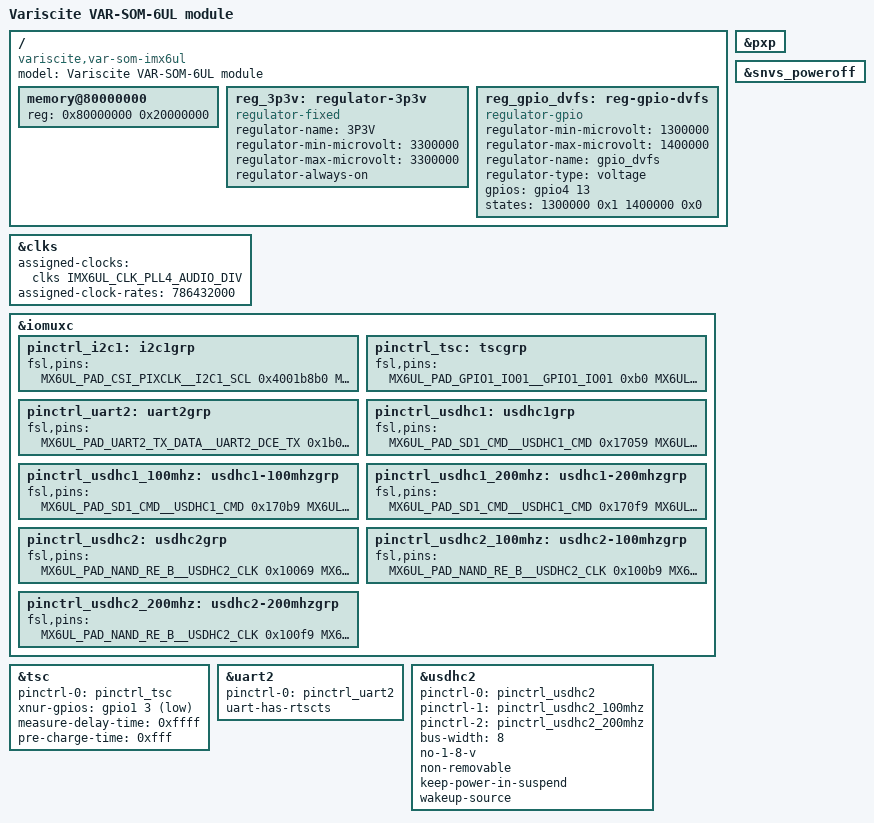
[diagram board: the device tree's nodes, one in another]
// SPDX-License-Identifier: GPL-2.0+
/*
 * Support for the common parts shared by all the different CPU options on
 * Variscite VAR-SOM-6UL Module
 *
 * Copyright 2019 Variscite Ltd.
 * Copyright 2025 Bootlin
 */

#include <dt-bindings/clock/imx6ul-clock.h>
#include <dt-bindings/gpio/gpio.h>

/ {
	model = "Variscite VAR-SOM-6UL module";
	compatible = "variscite,var-som-imx6ul", "fsl,imx6ul";

	memory@80000000 {
		device_type = "memory";
		reg = <0x80000000 0x20000000>;
	};

	reg_3p3v: regulator-3p3v {
		compatible = "regulator-fixed";
		regulator-name = "3P3V";
		regulator-min-microvolt = <3300000>;
		regulator-max-microvolt = <3300000>;
		regulator-always-on;
	};

	reg_gpio_dvfs: reg-gpio-dvfs {
		compatible = "regulator-gpio";
		regulator-min-microvolt = <1300000>;
		regulator-max-microvolt = <1400000>;
		regulator-name = "gpio_dvfs";
		regulator-type = "voltage";
		gpios = <&gpio4 13 GPIO_ACTIVE_HIGH>;
		states = <1300000 0x1
			  1400000 0x0>;
	};
};

&clks {
	assigned-clocks = <&clks IMX6UL_CLK_PLL4_AUDIO_DIV>;
	assigned-clock-rates = <786432000>;
};

&iomuxc {
	pinctrl_i2c1: i2c1grp {
		fsl,pins = <
			MX6UL_PAD_CSI_PIXCLK__I2C1_SCL		0x4001b8b0
			MX6UL_PAD_CSI_MCLK__I2C1_SDA		0x4001b8b0
		>;
	};

	pinctrl_tsc: tscgrp {
		fsl,pins = <
			MX6UL_PAD_GPIO1_IO01__GPIO1_IO01	0xb0
			MX6UL_PAD_GPIO1_IO02__GPIO1_IO02	0xb0
			MX6UL_PAD_GPIO1_IO03__GPIO1_IO03	0xb0
			MX6UL_PAD_GPIO1_IO04__GPIO1_IO04	0xb0
		>;
	};

	pinctrl_uart2: uart2grp {
		fsl,pins = <
			MX6UL_PAD_UART2_TX_DATA__UART2_DCE_TX	0x1b0b1
			MX6UL_PAD_UART2_RX_DATA__UART2_DCE_RX	0x1b0b1
			MX6UL_PAD_UART2_CTS_B__UART2_DCE_CTS	0x1b0b1
			MX6UL_PAD_UART2_RTS_B__UART2_DCE_RTS	0x1b0b1
		>;
	};

	pinctrl_usdhc1: usdhc1grp {
		fsl,pins = <
			MX6UL_PAD_SD1_CMD__USDHC1_CMD		0x17059
			MX6UL_PAD_SD1_CLK__USDHC1_CLK		0x17059
			MX6UL_PAD_SD1_DATA0__USDHC1_DATA0	0x17059
			MX6UL_PAD_SD1_DATA1__USDHC1_DATA1	0x17059
			MX6UL_PAD_SD1_DATA2__USDHC1_DATA2	0x17059
			MX6UL_PAD_SD1_DATA3__USDHC1_DATA3	0x17059
		>;
	};

	pinctrl_usdhc1_100mhz: usdhc1-100mhzgrp {
		fsl,pins = <
			MX6UL_PAD_SD1_CMD__USDHC1_CMD		0x170b9
			MX6UL_PAD_SD1_CLK__USDHC1_CLK		0x100b9
			MX6UL_PAD_SD1_DATA0__USDHC1_DATA0	0x170b9
			MX6UL_PAD_SD1_DATA1__USDHC1_DATA1	0x170b9
			MX6UL_PAD_SD1_DATA2__USDHC1_DATA2	0x170b9
			MX6UL_PAD_SD1_DATA3__USDHC1_DATA3	0x170b9
		>;
	};

	pinctrl_usdhc1_200mhz: usdhc1-200mhzgrp {
		fsl,pins = <
			MX6UL_PAD_SD1_CMD__USDHC1_CMD		0x170f9
			MX6UL_PAD_SD1_CLK__USDHC1_CLK		0x100f9
			MX6UL_PAD_SD1_DATA0__USDHC1_DATA0	0x170f9
			MX6UL_PAD_SD1_DATA1__USDHC1_DATA1	0x170f9
			MX6UL_PAD_SD1_DATA2__USDHC1_DATA2	0x170f9
			MX6UL_PAD_SD1_DATA3__USDHC1_DATA3	0x170f9
		>;
	};

	pinctrl_usdhc2: usdhc2grp {
		fsl,pins = <
			MX6UL_PAD_NAND_RE_B__USDHC2_CLK		0x10069
			MX6UL_PAD_NAND_WE_B__USDHC2_CMD		0x17059
			MX6UL_PAD_NAND_DATA00__USDHC2_DATA0	0x17059
			MX6UL_PAD_NAND_DATA01__USDHC2_DATA1	0x17059
			MX6UL_PAD_NAND_DATA02__USDHC2_DATA2	0x17059
			MX6UL_PAD_NAND_DATA03__USDHC2_DATA3	0x17059
			MX6UL_PAD_NAND_DATA04__USDHC2_DATA4	0x17059
			MX6UL_PAD_NAND_DATA05__USDHC2_DATA5	0x17059
			MX6UL_PAD_NAND_DATA06__USDHC2_DATA6	0x17059
			MX6UL_PAD_NAND_DATA07__USDHC2_DATA7	0x17059
		>;
	};

	pinctrl_usdhc2_100mhz: usdhc2-100mhzgrp {
		fsl,pins = <
			MX6UL_PAD_NAND_RE_B__USDHC2_CLK		0x100b9
			MX6UL_PAD_NAND_WE_B__USDHC2_CMD		0x170b9
			MX6UL_PAD_NAND_DATA00__USDHC2_DATA0	0x170b9
			MX6UL_PAD_NAND_DATA01__USDHC2_DATA1	0x170b9
			MX6UL_PAD_NAND_DATA02__USDHC2_DATA2	0x170b9
			MX6UL_PAD_NAND_DATA03__USDHC2_DATA3	0x170b9
			MX6UL_PAD_NAND_DATA04__USDHC2_DATA4	0x170b9
			MX6UL_PAD_NAND_DATA05__USDHC2_DATA5	0x170b9
			MX6UL_PAD_NAND_DATA06__USDHC2_DATA6	0x170b9
			MX6UL_PAD_NAND_DATA07__USDHC2_DATA7	0x170b9
		>;
	};

	pinctrl_usdhc2_200mhz: usdhc2-200mhzgrp {
		fsl,pins = <
			MX6UL_PAD_NAND_RE_B__USDHC2_CLK		0x100f9
			MX6UL_PAD_NAND_WE_B__USDHC2_CMD		0x170f9
			MX6UL_PAD_NAND_DATA00__USDHC2_DATA0	0x170f9
			MX6UL_PAD_NAND_DATA01__USDHC2_DATA1	0x170f9
			MX6UL_PAD_NAND_DATA02__USDHC2_DATA2	0x170f9
			MX6UL_PAD_NAND_DATA03__USDHC2_DATA3	0x170f9
			MX6UL_PAD_NAND_DATA04__USDHC2_DATA4	0x170f9
			MX6UL_PAD_NAND_DATA05__USDHC2_DATA5	0x170f9
			MX6UL_PAD_NAND_DATA06__USDHC2_DATA6	0x170f9
			MX6UL_PAD_NAND_DATA07__USDHC2_DATA7	0x170f9
		>;
	};
};

&pxp {
	status = "okay";
};

&snvs_poweroff {
	status = "okay";
};

&tsc {
	pinctrl-names = "default";
	pinctrl-0 = <&pinctrl_tsc>;
	xnur-gpios = <&gpio1 3 GPIO_ACTIVE_LOW>;
	measure-delay-time = <0xffff>;
	pre-charge-time = <0xfff>;
	status = "okay";
};

&uart2 {
	pinctrl-names = "default";
	pinctrl-0 = <&pinctrl_uart2>;
	uart-has-rtscts;
	status = "okay";
};

&usdhc2 {
	pinctrl-names = "default", "state_100mhz", "state_200mhz";
	pinctrl-0 = <&pinctrl_usdhc2>;
	pinctrl-1 = <&pinctrl_usdhc2_100mhz>;
	pinctrl-2 = <&pinctrl_usdhc2_200mhz>;
	bus-width = <8>;
	no-1-8-v;
	non-removable;
	keep-power-in-suspend;
	wakeup-source;
	status = "okay";
};
